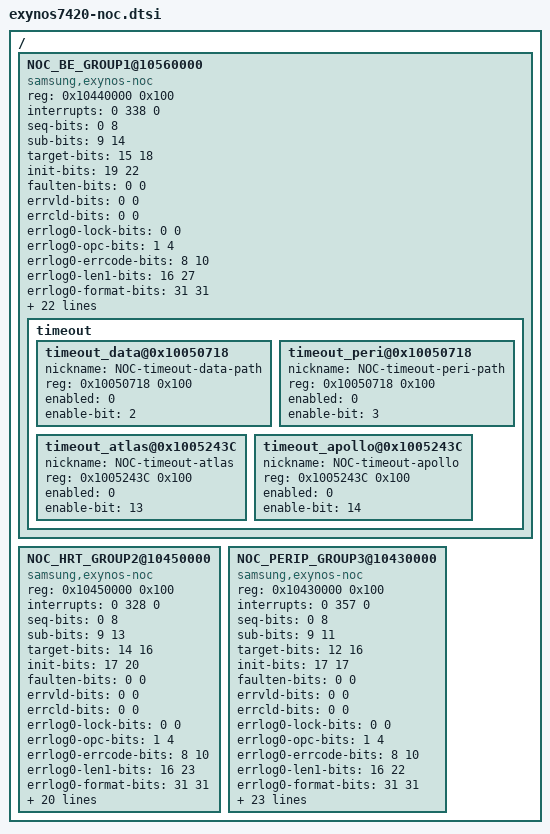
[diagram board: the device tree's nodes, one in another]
/*
 * SAMSUNG EXYNOS7420 SoC device tree source
 *
 * Copyright (c) 2014 Samsung Electronics Co., Ltd.
 *		http://www.samsung.com
 *
 * SAMSUNG EXYNOS7420 SoC device nodes are listed in this file.
 * EXYNOS7420 based board files can include this file and provide
 * values for board specfic bindings.
 *
 * This program is free software; you can redistribute it and/or modify
 * it under the terms of the GNU General Public License version 2 as
 * published by the Free Software Foundation.
 */

/ {
	NOC_BE_GROUP1@10560000 {
		/* BE - Group1 */
		compatible = "samsung,exynos-noc";
		reg = <0x10440000 0x100>;
		interrupts  = <0 338 0>;
		#address-cells = <1>;
		#size-cells = <0>;

		/* Group-bit description */
		seq-bits = <0 8>;
		sub-bits = <9 14>;
		target-bits = <15 18>;
		init-bits = <19 22>;

		/* Group detail bit description */
		faulten-bits = <0 0>;
		errvld-bits = <0 0>;
		errcld-bits = <0 0>;
		errlog0-lock-bits = <0 0>;
		errlog0-opc-bits = <1 4>;
		errlog0-errcode-bits = <8 10>;
		errlog0-len1-bits = <16 27>;
		errlog0-format-bits = <31 31>;
		errlog1-bits = <0 22>;
		errlog2-bits = <0 0>;
		errlog3-bits = <0 31>;
		errlog4-bits = <0 3>;
		errlog5-bits = <0 22>;

		/* init, target, subrage detail description */
		init-num = <16>;
		target-num = <16>;
		sub-num = <64>;
		sub-array = <994>;
		init-desc =	"APB_BUS0_NRT",
				"APB_BUS1_NRT",
				"APB_CORE_NRT",
				"AUD",
				"CAM1",
				"FSYS0",
				"FSYS1",
				"G3D0",
				"G3D1",
				"IMEM",
				"ISP",
				"MFC0",
				"MFC1",
				"MSCL0",
				"MSCL1",
				"APB_CORE_NRT_TO";
		target-desc =	"MEM_S0",
				"MEM_S1",
				"P_CORE_T",
				"SER_BUS0_NRT",
				"SER_BUS1_NRT",
				"SER_CORE_NRT",
				"TNSP0(DRAM CH0)",
				"TNSP1(DRAM CH1)",
				"TNSP2(DRAM CH2)",
				"TNSP3(DRAM_CH3)",
				"TNSP_ISP",
				"SER_CORE_NRT_TO";
		sub-index = <192 1280 2368 3200 3456 3457 3458 3459 3460 3461 3462 3463 3464 3465 3466 3467
				3468 3469 3470 3471 3472 3520 3521 3522 3523 3524 3525 3526 3527 3528 3529 3530
				3531 3532 3533 3534 3535 3536 3584 3585 3586 3587 3588 3589 3590 3591 3592 3593
				3594 3595 3596 3597 3598 3599 3600 3648 3649 3650 3651 3652 3653 3654 3655 3656
				3657 3658 3659 3660 3661 3662 3663 3664 4224 4480 4481 4482 4483 4484 4485 4486
				4487 4488 4489 4490 4491 4492 4493 4494 4495 4496 4544 4545 4546 4547 4548 4549
				4550 4551 4552 4553 4554 4555 4556 4557 4558 4559 4560 4608 4609 4610 4611 4612
				4613 4614 4615 4616 4617 4618 4619 4620 4621 4622 4623 4624 4672 4673 4674 4675
				4676 4677 4678 4679 4680 4681 4682 4683 4684 4685 4686 4687 4688 4736 5248 5504
				5505 5506 5507 5508 5509 5510 5511 5512 5513 5514 5515 5516 5517 5518 5519 5520
				5568 5569 5570 5571 5572 5573 5574 5575 5576 5577 5578 5579 5580 5581 5582 5583
				5584 5632 5633 5634 5635 5636 5637 5638 5639 5640 5641 5642 5643 5644 5645 5646
				5647 5648 5696 5697 5698 5699 5700 5701 5702 5703 5704 5705 5706 5707 5708 5709
				5710 5711 5712 6272 6528 6529 6530 6531 6532 6533 6534 6535 6536 6537 6538 6539
				6540 6541 6542 6543 6544 6592 6593 6594 6595 6596 6597 6598 6599 6600 6601 6602
				6603 6604 6605 6606 6607 6608 6656 6657 6658 6659 6660 6661 6662 6663 6664 6665
				6666 6667 6668 6669 6670 6671 6672 6720 6721 6722 6723 6724 6725 6726 6727 6728
				6729 6730 6731 6732 6733 6734 6735 6736 7168 7169 7170 7171 7172 7552 7553 7554
				7555 7556 7557 7558 7559 7560 7561 7562 7563 7564 7565 7566 7567 7568 7569 7570
				7571 7572 7573 7574 7575 7576 7577 7578 7579 7580 7581 7582 7583 7584 7585 7680
				7681 7682 7683 7684 7685 7686 7687 7688 7689 7690 7691 7692 7693 7694 7695 7696
				7697 7698 7699 7700 7701 7702 7703 7704 7705 7706 7707 7708 7709 7710 7711 7712
				7713 8256 8257 8258 8259 8260 8640 8641 8642 8643 8644 8645 8646 8647 8648 8649
				8650 8651 8652 8653 8654 8655 8656 8657 8658 8659 8660 8661 8662 8663 8664 8665
				8666 8667 8668 8669 8670 8671 8672 8673 8768 8769 8770 8771 8772 8773 8774 8775
				8776 8777 8778 8779 8780 8781 8782 8783 8784 8785 8786 8787 8788 8789 8790 8791
				8792 8793 8794 8795 8796 8797 8798 8799 8800 8801 9216 9217 9218 9219 9220 9280
				9281 9282 9283 9284 9344 9345 9600 9601 9602 9603 9604 9605 9606 9607 9608 9609
				9610 9611 9612 9613 9614 9615 9616 9617 9618 9619 9620 9621 9622 9623 9624 9625
				9626 9627 9628 9629 9630 9631 9632 9633 9664 9665 9666 9667 9668 9669 9670 9671
				9672 9673 9674 9675 9676 9677 9678 9679 9680 9681 9682 9683 9684 9685 9686 9687
				9688 9689 9690 9691 9692 9693 9694 9695 9696 9697 9728 9729 9730 9731 9732 9733
				9734 9735 9736 9737 9738 9739 9740 9741 9742 9743 9744 9745 9746 9747 9748 9749
				9750 9751 9752 9753 9754 9755 9756 9757 9758 9759 9760 9761 9792 9793 9794 9795
				9796 9797 9798 9799 9800 9801 9802 9803 9804 9805 9806 9807 9808 9809 9810 9811
				9812 9813 9814 9815 9816 9817 9818 9819 9820 9821 9822 9823 9824 9825 10624
				10625 10626 10627 10628 10629 10630 10631 10632 10633 10634 10635 10636 10637
				10638 10639 10640 10688 10689 10690 10691 10692 10693 10694 10695 10696 10697
				10698 10699 10700 10701 10702 10703 10704 10752 10753 10754 10755 10756 10757
				10758 10759 10760 10761 10762 10763 10764 10765 10766 10767 10768 10816 10817
				10818 10819 10820 10821 10822 10823 10824 10825 10826 10827 10828 10829 10830
				10831 10832 10880 11648 11649 11650 11651 11652 11653 11654 11655 11656 11657
				11658 11659 11660 11661 11662 11663 11664 11712 11713 11714 11715 11716 11717
				11718 11719 11720 11721 11722 11723 11724 11725 11726 11727 11728 11776 11777
				11778 11779 11780 11781 11782 11783 11784 11785 11786 11787 11788 11789 11790
				11791 11792 11840 11841 11842 11843 11844 11845 11846 11847 11848 11849 11850
				11851 11852 11853 11854 11855 11856 12672 12673 12674 12675 12676 12677 12678
				12679 12680 12681 12682 12683 12684 12685 12686 12687 12688 12736 12737 12738
				12739 12740 12741 12742 12743 12744 12745 12746 12747 12748 12749 12750 12751
				12752 12800 12801 12802 12803 12804 12805 12806 12807 12808 12809 12810 12811
				12812 12813 12814 12815 12816 12864 12865 12866 12867 12868 12869 12870 12871
				12872 12873 12874 12875 12876 12877 12878 12879 12880 13696 13697 13698 13699
				13700 13701 13702 13703 13704 13705 13706 13707 13708 13709 13710 13711 13712
				13760 13761 13762 13763 13764 13765 13766 13767 13768 13769 13770 13771 13772
				13773 13774 13775 13776 13824 13825 13826 13827 13828 13829 13830 13831 13832
				13833 13834 13835 13836 13837 13838 13839 13840 13888 13889 13890 13891 13892
				13893 13894 13895 13896 13897 13898 13899 13900 13901 13902 13903 13904 14336
				14337 14338 14339 14340 14400 14401 14402 14403 14404 14720 14721 14722 14723
				14724 14725 14726 14727 14728 14729 14730 14731 14732 14733 14734 14735 14736
				14737 14738 14739 14740 14741 14742 14743 14744 14745 14746 14747 14748 14749
				14750 14751 14752 14753 14784 14785 14786 14787 14788 14789 14790 14791 14792
				14793 14794 14795 14796 14797 14798 14799 14800 14801 14802 14803 14804 14805
				14806 14807 14808 14809 14810 14811 14812 14813 14814 14815 14816 14817 14848
				14849 14850 14851 14852 14853 14854 14855 14856 14857 14858 14859 14860 14861
				14862 14863 14864 14865 14866 14867 14868 14869 14870 14871 14872 14873 14874
				14875 14876 14877 14878 14879 14880 14881 14912 14913 14914 14915 14916 14917
				14918 14919 14920 14921 14922 14923 14924 14925 14926 14927 14928 14929 14930
				14931 14932 14933 14934 14935 14936 14937 14938 14939 14940 14941 14942 14943
				14944 14945 16064>;
		sub-addr = <0x13450000 0x14850000 0x10560000 0x0 0x0 0x0 0x1080 0x2100 0x3180 0x4080 0x5000
				0x6180 0x7100 0x8100 0x9180 0xa000 0xb080 0xc180 0xd100 0xe080 0xf000 0x80 0x80
				0x1000 0x2180 0x3100 0x4000 0x5080 0x6100 0x7180 0x8180 0x9100 0xa080 0xb000
				0xc100 0xd180 0xe000 0xf080 0x100 0x100 0x1180 0x2000 0x3080 0x4180 0x5100
				0x6080 0x7000 0x8000 0x9080 0xa100 0xb180 0xc080 0xd000 0xe180 0xf100 0x180
				0x180 0x1100 0x2080 0x3000 0x4100 0x5180 0x6000 0x7080 0x8080 0x9000 0xa180
				0xb100 0xc000 0xd080 0xe100 0xf180 0x0 0x0 0x0 0x1080 0x2100 0x3180 0x4080
				0x5000 0x6180 0x7100 0x8100 0x9180 0xa000 0xb080 0xc180 0xd100 0xe080 0xf000
				0x80 0x80 0x1000 0x2180 0x3100 0x4000 0x5080 0x6100 0x7180 0x8180 0x9100 0xa080
				0xb000 0xc100 0xd180 0xe000 0xf080 0x100 0x100 0x1180 0x2000 0x3080 0x4180
				0x5100 0x6080 0x7000 0x8000 0x9080 0xa100 0xb180 0xc080 0xd000 0xe180 0xf100
				0x180 0x180 0x1100 0x2080 0x3000 0x4100 0x5180 0x6000 0x7080 0x8080 0x9000
				0xa180 0xb100 0xc000 0xd080 0xe100 0xf180 0xCAFE 0x0 0x0 0x0 0x1080
				0x2100 0x3180 0x4080 0x5000 0x6180 0x7100 0x8100 0x9180 0xa000 0xb080 0xc180
				0xd100 0xe080 0xf000 0x80 0x80 0x1000 0x2180 0x3100 0x4000 0x5080 0x6100 0x7180
				0x8180 0x9100 0xa080 0xb000 0xc100 0xd180 0xe000 0xf080 0x100 0x100 0x1180
				0x2000 0x3080 0x4180 0x5100 0x6080 0x7000 0x8000 0x9080 0xa100 0xb180 0xc080
				0xd000 0xe180 0xf100 0x180 0x180 0x1100 0x2080 0x3000 0x4100 0x5180 0x6000
				0x7080 0x8080 0x9000 0xa180 0xb100 0xc000 0xd080 0xe100 0xf180 0x0 0x0 0x0
				0x1080 0x2100 0x3180 0x4080 0x5000 0x6180 0x7100 0x8100 0x9180 0xa000 0xb080
				0xc180 0xd100 0xe080 0xf000 0x80 0x80 0x1000 0x2180 0x3100 0x4000 0x5080 0x6100
				0x7180 0x8180 0x9100 0xa080 0xb000 0xc100 0xd180 0xe000 0xf080 0x100 0x100
				0x1180 0x2000 0x3080 0x4180 0x5100 0x6080 0x7000 0x8000 0x9080 0xa100 0xb180
				0xc080 0xd000 0xe180 0xf100 0x180 0x180 0x1100 0x2080 0x3000 0x4100 0x5180
				0x6000 0x7080 0x8080 0x9000 0xa180 0xb100 0xc000 0xd080 0xe100 0xf180
				0xCAFE 0xCAFE 0xCAFE 0xCAFE 0xCAFE 0x0 0x0 0x1080
				0x2100 0x3180 0x4080 0x5000 0x6180 0x7100 0x8100 0x9180 0xa000 0xb080 0xc180
				0xd100 0xe080 0xf000 0x0 0x0 0x1080 0x2100 0x3180 0x4080 0x5000 0x6180 0x7100
				0x8100 0x9180 0xa000 0xb080 0xc180 0xd100 0xe080 0xf000 0x100 0x100 0x1180
				0x2000 0x3080 0x4180 0x5100 0x6080 0x7000 0x8000 0x9080 0xa100 0xb180 0xc080
				0xd000 0xe180 0xf100 0x100 0x100 0x1180 0x2000 0x3080 0x4180 0x5100 0x6080
				0x7000 0x8000 0x9080 0xa100 0xb180 0xc080 0xd000 0xe180 0xf100 0xCAFE
				0xCAFE 0xCAFE 0xCAFE 0xCAFE 0x80 0x80 0x1000 0x2180
				0x3100 0x4000 0x5080 0x6100 0x7180 0x8180 0x9100 0xa080 0xb000 0xc100 0xd180
				0xe000 0xf080 0x80 0x80 0x1000 0x2180 0x3100 0x4000 0x5080 0x6100 0x7180 0x8180
				0x9100 0xa080 0xb000 0xc100 0xd180 0xe000 0xf080 0x180 0x180 0x1100 0x2080
				0x3000 0x4100 0x5180 0x6000 0x7080 0x8080 0x9000 0xa180 0xb100 0xc000 0xd080
				0xe100 0xf180 0x180 0x180 0x1100 0x2080 0x3000 0x4100 0x5180 0x6000 0x7080
				0x8080 0x9000 0xa180 0xb100 0xc000 0xd080 0xe100 0xf180 0xCAFE
				0xCAFE 0xCAFE 0xCAFE 0xCAFE 0xCAFE 0xCAFE
				0xCAFE 0xCAFE 0xCAFE 0x0 0x0 0x0 0x0 0x1080 0x2100 0x3180
				0x4080 0x5000 0x6180 0x7100 0x8100 0x9180 0xa000 0xb080 0xc180 0xd100 0xe080
				0xf000 0x0 0x0 0x1080 0x2100 0x3180 0x4080 0x5000 0x6180 0x7100 0x8100 0x9180
				0xa000 0xb080 0xc180 0xd100 0xe080 0xf000 0x80 0x80 0x1000 0x2180 0x3100 0x4000
				0x5080 0x6100 0x7180 0x8180 0x9100 0xa080 0xb000 0xc100 0xd180 0xe000 0xf080
				0x80 0x80 0x1000 0x2180 0x3100 0x4000 0x5080 0x6100 0x7180 0x8180 0x9100 0xa080
				0xb000 0xc100 0xd180 0xe000 0xf080 0x100 0x100 0x1180 0x2000 0x3080 0x4180
				0x5100 0x6080 0x7000 0x8000 0x9080 0xa100 0xb180 0xc080 0xd000 0xe180 0xf100
				0x100 0x100 0x1180 0x2000 0x3080 0x4180 0x5100 0x6080 0x7000 0x8000 0x9080
				0xa100 0xb180 0xc080 0xd000 0xe180 0xf100 0x180 0x180 0x1100 0x2080 0x3000
				0x4100 0x5180 0x6000 0x7080 0x8080 0x9000 0xa180 0xb100 0xc000 0xd080 0xe100
				0xf180 0x180 0x180 0x1100 0x2080 0x3000 0x4100 0x5180 0x6000 0x7080 0x8080
				0x9000 0xa180 0xb100 0xc000 0xd080 0xe100 0xf180 0x0 0x0 0x1080 0x2100 0x3180
				0x4080 0x5000 0x6180 0x7100 0x8100 0x9180 0xa000 0xb080 0xc180 0xd100 0xe080
				0xf000 0x80 0x80 0x1000 0x2180 0x3100 0x4000 0x5080 0x6100 0x7180 0x8180 0x9100
				0xa080 0xb000 0xc100 0xd180 0xe000 0xf080 0x100 0x100 0x1180 0x2000 0x3080
				0x4180 0x5100 0x6080 0x7000 0x8000 0x9080 0xa100 0xb180 0xc080 0xd000 0xe180
				0xf100 0x180 0x180 0x1100 0x2080 0x3000 0x4100 0x5180 0x6000 0x7080 0x8080
				0x9000 0xa180 0xb100 0xc000 0xd080 0xe100 0xf180 0xCAFE 0x0 0x0 0x1080
				0x2100 0x3180 0x4080 0x5000 0x6180 0x7100 0x8100 0x9180 0xa000 0xb080 0xc180
				0xd100 0xe080 0xf000 0x80 0x80 0x1000 0x2180 0x3100 0x4000 0x5080 0x6100 0x7180
				0x8180 0x9100 0xa080 0xb000 0xc100 0xd180 0xe000 0xf080 0x100 0x100 0x1180
				0x2000 0x3080 0x4180 0x5100 0x6080 0x7000 0x8000 0x9080 0xa100 0xb180 0xc080
				0xd000 0xe180 0xf100 0x180 0x180 0x1100 0x2080 0x3000 0x4100 0x5180 0x6000
				0x7080 0x8080 0x9000 0xa180 0xb100 0xc000 0xd080 0xe100 0xf180 0x0 0x0 0x1080
				0x2100 0x3180 0x4080 0x5000 0x6180 0x7100 0x8100 0x9180 0xa000 0xb080 0xc180
				0xd100 0xe080 0xf000 0x80 0x80 0x1000 0x2180 0x3100 0x4000 0x5080 0x6100 0x7180
				0x8180 0x9100 0xa080 0xb000 0xc100 0xd180 0xe000 0xf080 0x100 0x100 0x1180
				0x2000 0x3080 0x4180 0x5100 0x6080 0x7000 0x8000 0x9080 0xa100 0xb180 0xc080
				0xd000 0xe180 0xf100 0x180 0x180 0x1100 0x2080 0x3000 0x4100 0x5180 0x6000
				0x7080 0x8080 0x9000 0xa180 0xb100 0xc000 0xd080 0xe100 0xf180 0x0 0x0 0x1080
				0x2100 0x3180 0x4080 0x5000 0x6180 0x7100 0x8100 0x9180 0xa000 0xb080 0xc180
				0xd100 0xe080 0xf000 0x80 0x80 0x1000 0x2180 0x3100 0x4000 0x5080 0x6100 0x7180
				0x8180 0x9100 0xa080 0xb000 0xc100 0xd180 0xe000 0xf080 0x100 0x100 0x1180
				0x2000 0x3080 0x4180 0x5100 0x6080 0x7000 0x8000 0x9080 0xa100 0xb180 0xc080
				0xd000 0xe180 0xf100 0x180 0x180 0x1100 0x2080 0x3000 0x4100 0x5180 0x6000
				0x7080 0x8080 0x9000 0xa180 0xb100 0xc000 0xd080 0xe100 0xf180 0xCAFE
				0xCAFE 0xCAFE 0xCAFE 0xCAFE 0xCAFE 0xCAFE
				0xCAFE 0xCAFE 0xCAFE 0x0 0x0 0x1080 0x2100 0x3180 0x4080
				0x5000 0x6180 0x7100 0x8100 0x9180 0xa000 0xb080 0xc180 0xd100 0xe080 0xf000
				0x0 0x0 0x1080 0x2100 0x3180 0x4080 0x5000 0x6180 0x7100 0x8100 0x9180 0xa000
				0xb080 0xc180 0xd100 0xe080 0xf000 0x80 0x80 0x1000 0x2180 0x3100 0x4000 0x5080
				0x6100 0x7180 0x8180 0x9100 0xa080 0xb000 0xc100 0xd180 0xe000 0xf080 0x80 0x80
				0x1000 0x2180 0x3100 0x4000 0x5080 0x6100 0x7180 0x8180 0x9100 0xa080 0xb000
				0xc100 0xd180 0xe000 0xf080 0x100 0x100 0x1180 0x2000 0x3080 0x4180 0x5100
				0x6080 0x7000 0x8000 0x9080 0xa100 0xb180 0xc080 0xd000 0xe180 0xf100 0x100
				0x100 0x1180 0x2000 0x3080 0x4180 0x5100 0x6080 0x7000 0x8000 0x9080 0xa100
				0xb180 0xc080 0xd000 0xe180 0xf100 0x180 0x180 0x1100 0x2080 0x3000 0x4100
				0x5180 0x6000 0x7080 0x8080 0x9000 0xa180 0xb100 0xc000 0xd080 0xe100 0xf180
				0x180 0x180 0x1100 0x2080 0x3000 0x4100 0x5180 0x6000 0x7080 0x8080 0x9000
				0xa180 0xb100 0xc000 0xd080 0xe100 0xf180 0x10440000>;

		timeout {
			#address-cells = <1>;
			#size-cells = <1>;
			timeout_data@0x10050718 {
				nickname = "NOC-timeout-data-path";
				reg = <0x10050718 0x100>;
				enabled = <0>;
				enable-bit = <2>;
			};
			timeout_peri@0x10050718 {
				nickname = "NOC-timeout-peri-path";
				reg = <0x10050718 0x100>;
				enabled = <0>;
				enable-bit = <3>;
			};
			timeout_atlas@0x1005243C {
				nickname = "NOC-timeout-atlas";
				reg = <0x1005243C 0x100>;
				enabled = <0>;
				enable-bit = <13>;
			};
			timeout_apollo@0x1005243C {
				nickname = "NOC-timeout-apollo";
				reg = <0x1005243C 0x100>;
				enabled = <0>;
				enable-bit = <14>;
			};
		};
	};

	NOC_HRT_GROUP2@10450000 {
		/* HRT */
		compatible = "samsung,exynos-noc";
		reg = <0x10450000 0x100>;
		interrupts  = <0 328 0>;
		#address-cells = <1>;
		#size-cells = <0>;

		/* Group-bit description */
		seq-bits = <0 8>;
		sub-bits = <9 13>;
		target-bits = <14 16>;
		init-bits = <17 20>;

		/* Group detail bit rescription */
		faulten-bits = <0 0>;
		errvld-bits = <0 0>;
		errcld-bits = <0 0>;
		errlog0-lock-bits = <0 0>;
		errlog0-opc-bits = <1 4>;
		errlog0-errcode-bits = <8 10>;
		errlog0-len1-bits = <16 23>;
		errlog0-format-bits = <31 31>;
		errlog1-bits = <0 20>;
		errlog2-bits = <0 0>;
		errlog3-bits = <0 31>;
		errlog4-bits = <0 3>;
		errlog5-bits = <0 16>;

		/* init, target, subrage detail description */
		init-num = <16>;
		target-num = <8>;
		sub-num = <32>;
		sub-array = <479>;
		init-desc =	"APB_BUS0_RT",
				"APB_CORE_RT",
				"CAM0",
				"DISP0",
				"DISP1",
				"INSP0(From BE)",
				"INSP1(From BE)",
				"INSP2(From BE)",
				"INSP3(From BE)",
				"INSP_ISP",
				"VPP0",
				"VPP1",
				"APB_CORE_RT_TO";
		target-desc =	"MEM0_0",
				"MEM1_0",
				"MEM2_0",
				"MEM3_0",
				"SER_BUS0_RT",
				"SER_CORE_RT",
				"SER_CORE_RT_TO";
		sub-index = <128 416 512 513 514 515 516 517 518 519 520 521 522 523 524 525 526 527 528 544
				545 546 547 548 549 550 551 552 553 554 555 556 557 558 559 560 576 577 578 579
				580 581 582 583 584 585 586 587 588 589 590 591 592 608 609 610 611 612 613 614
				615 616 617 618 619 620 621 622 623 624 768 769 770 771 772 773 774 775 776 777
				778 779 780 781 782 783 784 800 801 802 803 804 805 806 807 808 809 810 811 812
				813 814 815 816 832 833 834 835 836 837 838 839 840 841 842 843 844 845 846 847
				848 864 865 866 867 868 869 870 871 872 873 874 875 876 877 878 879 880 1024
				1025 1026 1027 1028 1029 1030 1031 1032 1033 1034 1035 1036 1037 1038 1039 1040
				1056 1057 1058 1059 1060 1061 1062 1063 1064 1065 1066 1067 1068 1069 1070 1071
				1072 1088 1089 1090 1091 1092 1093 1094 1095 1096 1097 1098 1099 1100 1101 1102
				1103 1104 1120 1121 1122 1123 1124 1125 1126 1127 1128 1129 1130 1131 1132 1133
				1134 1135 1136 1280 1281 1282 1283 1284 1285 1286 1287 1288 1289 1290 1291 1292
				1293 1294 1295 1296 1568 1569 1570 1571 1572 1573 1574 1575 1576 1577 1578 1579
				1580 1581 1582 1583 1584 1856 1857 1858 1859 1860 1861 1862 1863 1864 1865 1866
				1867 1868 1869 1870 1871 1872 2144 2145 2146 2147 2148 2149 2150 2151 2152 2153
				2154 2155 2156 2157 2158 2159 2160 2304 2305 2306 2307 2308 2309 2310 2311 2312
				2313 2314 2315 2316 2317 2318 2319 2320 2336 2337 2338 2339 2340 2341 2342 2343
				2344 2345 2346 2347 2348 2349 2350 2351 2352 2368 2369 2370 2371 2372 2373 2374
				2375 2376 2377 2378 2379 2380 2381 2382 2383 2384 2400 2401 2402 2403 2404 2405
				2406 2407 2408 2409 2410 2411 2412 2413 2414 2415 2416 2560 2561 2562 2563 2564
				2565 2566 2567 2568 2569 2570 2571 2572 2573 2574 2575 2576 2592 2593 2594 2595
				2596 2597 2598 2599 2600 2601 2602 2603 2604 2605 2606 2607 2608 2624 2625 2626
				2627 2628 2629 2630 2631 2632 2633 2634 2635 2636 2637 2638 2639 2640 2656 2657
				2658 2659 2660 2661 2662 2663 2664 2665 2666 2667 2668 2669 2670 2671 2672 2816
				2817 2818 2819 2820 2821 2822 2823 2824 2825 2826 2827 2828 2829 2830 2831 2832
				2848 2849 2850 2851 2852 2853 2854 2855 2856 2857 2858 2859 2860 2861 2862 2863
				2864 2880 2881 2882 2883 2884 2885 2886 2887 2888 2889 2890 2891 2892 2893 2894
				2895 2896 2912 2913 2914 2915 2916 2917 2918 2919 2920 2921 2922 2923 2924 2925
				2926 2927 2928 3264>;
		sub-addr = <0x13460000 0x10550000 0x0 0x0 0x1080 0x2100 0x3180 0x4080 0x5000 0x6180 0x7100
				0x8100 0x9180 0xa000 0xb080 0xc180 0xd100 0xe080 0xf000 0x80 0x80 0x1000 0x2180
				0x3100 0x4000 0x5080 0x6100 0x7180 0x8180 0x9100 0xa080 0xb000 0xc100 0xd180
				0xe000 0xf080 0x100 0x100 0x1180 0x2000 0x3080 0x4180 0x5100 0x6080 0x7000
				0x8000 0x9080 0xa100 0xb180 0xc080 0xd000 0xe180 0xf100 0x180 0x180 0x1100
				0x2080 0x3000 0x4100 0x5180 0x6000 0x7080 0x8080 0x9000 0xa180 0xb100 0xc000
				0xd080 0xe100 0xf180 0x0 0x0 0x1080 0x2100 0x3180 0x4080 0x5000 0x6180 0x7100
				0x8100 0x9180 0xa000 0xb080 0xc180 0xd100 0xe080 0xf000 0x80 0x80 0x1000 0x2180
				0x3100 0x4000 0x5080 0x6100 0x7180 0x8180 0x9100 0xa080 0xb000 0xc100 0xd180
				0xe000 0xf080 0x100 0x100 0x1180 0x2000 0x3080 0x4180 0x5100 0x6080 0x7000
				0x8000 0x9080 0xa100 0xb180 0xc080 0xd000 0xe180 0xf100 0x180 0x180 0x1100
				0x2080 0x3000 0x4100 0x5180 0x6000 0x7080 0x8080 0x9000 0xa180 0xb100 0xc000
				0xd080 0xe100 0xf180 0x0 0x0 0x1080 0x2100 0x3180 0x4080 0x5000 0x6180 0x7100
				0x8100 0x9180 0xa000 0xb080 0xc180 0xd100 0xe080 0xf000 0x80 0x80 0x1000 0x2180
				0x3100 0x4000 0x5080 0x6100 0x7180 0x8180 0x9100 0xa080 0xb000 0xc100 0xd180
				0xe000 0xf080 0x100 0x100 0x1180 0x2000 0x3080 0x4180 0x5100 0x6080 0x7000
				0x8000 0x9080 0xa100 0xb180 0xc080 0xd000 0xe180 0xf100 0x180 0x180 0x1100
				0x2080 0x3000 0x4100 0x5180 0x6000 0x7080 0x8080 0x9000 0xa180 0xb100 0xc000
				0xd080 0xe100 0xf180 0x0 0x0 0x1080 0x2100 0x3180 0x4080 0x5000 0x6180 0x7100
				0x8100 0x9180 0xa000 0xb080 0xc180 0xd100 0xe080 0xf000 0x80 0x80 0x1000 0x2180
				0x3100 0x4000 0x5080 0x6100 0x7180 0x8180 0x9100 0xa080 0xb000 0xc100 0xd180
				0xe000 0xf080 0x100 0x100 0x1180 0x2000 0x3080 0x4180 0x5100 0x6080 0x7000
				0x8000 0x9080 0xa100 0xb180 0xc080 0xd000 0xe180 0xf100 0x180 0x180 0x1100
				0x2080 0x3000 0x4100 0x5180 0x6000 0x7080 0x8080 0x9000 0xa180 0xb100 0xc000
				0xd080 0xe100 0xf180 0x0 0x0 0x1080 0x2100 0x3180 0x4080 0x5000 0x6180 0x7100
				0x8100 0x9180 0xa000 0xb080 0xc180 0xd100 0xe080 0xf000 0x80 0x80 0x1000 0x2180
				0x3100 0x4000 0x5080 0x6100 0x7180 0x8180 0x9100 0xa080 0xb000 0xc100 0xd180
				0xe000 0xf080 0x100 0x100 0x1180 0x2000 0x3080 0x4180 0x5100 0x6080 0x7000
				0x8000 0x9080 0xa100 0xb180 0xc080 0xd000 0xe180 0xf100 0x180 0x180 0x1100
				0x2080 0x3000 0x4100 0x5180 0x6000 0x7080 0x8080 0x9000 0xa180 0xb100 0xc000
				0xd080 0xe100 0xf180 0x0 0x0 0x1080 0x2100 0x3180 0x4080 0x5000 0x6180 0x7100
				0x8100 0x9180 0xa000 0xb080 0xc180 0xd100 0xe080 0xf000 0x80 0x80 0x1000 0x2180
				0x3100 0x4000 0x5080 0x6100 0x7180 0x8180 0x9100 0xa080 0xb000 0xc100 0xd180
				0xe000 0xf080 0x100 0x100 0x1180 0x2000 0x3080 0x4180 0x5100 0x6080 0x7000
				0x8000 0x9080 0xa100 0xb180 0xc080 0xd000 0xe180 0xf100 0x180 0x180 0x1100
				0x2080 0x3000 0x4100 0x5180 0x6000 0x7080 0x8080 0x9000 0xa180 0xb100 0xc000
				0xd080 0xe100 0xf180 0x0 0x0 0x1080 0x2100 0x3180 0x4080 0x5000 0x6180 0x7100
				0x8100 0x9180 0xa000 0xb080 0xc180 0xd100 0xe080 0xf000 0x80 0x80 0x1000 0x2180
				0x3100 0x4000 0x5080 0x6100 0x7180 0x8180 0x9100 0xa080 0xb000 0xc100 0xd180
				0xe000 0xf080 0x100 0x100 0x1180 0x2000 0x3080 0x4180 0x5100 0x6080 0x7000
				0x8000 0x9080 0xa100 0xb180 0xc080 0xd000 0xe180 0xf100 0x180 0x180 0x1100
				0x2080 0x3000 0x4100 0x5180 0x6000 0x7080 0x8080 0x9000 0xa180 0xb100 0xc000
				0xd080 0xe100 0xf180 0x10450000>;
	};

	NOC_PERIP_GROUP3@10430000 {
		/* PERI */
		compatible = "samsung,exynos-noc";
		reg = <0x10430000 0x100>;
		interrupts  = <0 357 0>;
		#address-cells = <1>;
		#size-cells = <0>;

		/* Group-bit description */
		seq-bits = <0 8>;
		sub-bits = <9 11>;
		target-bits = <12 16>;
		init-bits = <17 17>;

		/* Group detail bit rescription */
		faulten-bits = <0 0>;
		errvld-bits = <0 0>;
		errcld-bits = <0 0>;
		errlog0-lock-bits = <0 0>;
		errlog0-opc-bits = <1 4>;
		errlog0-errcode-bits = <8 10>;
		errlog0-len1-bits = <16 22>;
		errlog0-format-bits = <31 31>;
		errlog1-bits = <0 17>;
		errlog2-bits = <0 0>;
		errlog3-bits = <0 25>;
		errlog4-bits = <0 0>;
		errlog5-bits = <0 12>;

		/* init, target, subrage detail description */
		init-num = <2>;
		target-num = <32>;
		sub-num = <8>;
		sub-array = <52>;
		init-desc =	"APB_PERI",
				"P_CCI";
		target-desc =	"P_CORE0",
				"P_CORE1",
				"P_CORE(CORESIGHT)",
				"P_BUS0SFR",
				"P_BUS1SFR",
				"P_MIF0",
				"P_MIF1",
				"P_MIF2",
				"P_MIF3",
				"SER_CORE_PERI_TO",
				"TNSP_P_APL",
				"TNSP_P_ATL",
				"TNSP_P_AUD",
				"TNSP_P_CAM0",
				"TNSP_P_CAM1",
				"TNSP_P_DISP",
				"TNSP_P_FSYS0",
				"TNSP_P_FSYS1",
				"TNSP_P_G3D",
				"TNSP_P_MFC",
				"TNSP_P_MSCL",
				"TNSP_P_PERIC0",
				"TNSP_P_PERIC1",
				"TNSP_P_PERIS",
				"TNSP_P_VPP";
		sub-index = <288 352 384 256 257 258 288 320 416 417 418 448 449 450 480 481 482 512 513 514
				576 608 640 641 672 673 704 736 768 769 770 771 772 773 774 775 800 801 802 803
				804 805 806 807 832 864 896 928 960 961 992 1024>;
		sub-addr = <0x10430000 0x13400000 0x14800000 0x10500000 0x10500000 0x10600000 0x10400000
				0x16000000 0x10830000 0x10860000 0x10800000 0x10930000 0x10960000 0x10900000
				0x10a30000 0x10a60000 0x10a00000 0x10b30000 0x10b60000 0x10b00000 0x11900000
				0x11800000 0x11400000 0x3000000 0x14000000 0x14400000 0x14000000 0x13800000
				0x15610000 0x15650000 0x156a0000 0x10f00000 0x10e00000 0x15400000 0x15500000
				0x18000000 0x15570000 0x15540000 0x15600000 0x15700000 0x2000000 0x0 0x4000000
				0x1c000000 0x14a00000 0x15200000 0x15000000 0x13600000 0x14e00000 0x14c00000
				0x10000000 0x13e00000>;
	};
};
